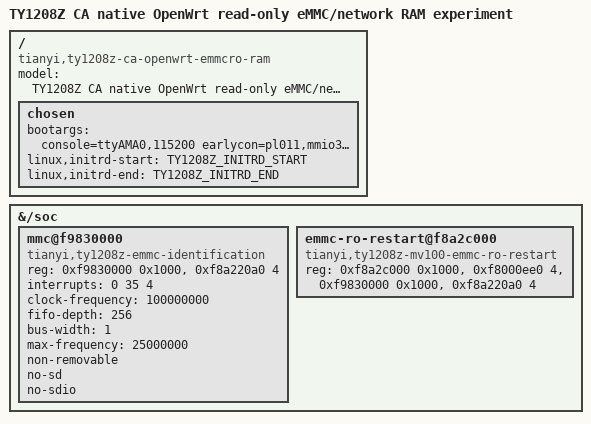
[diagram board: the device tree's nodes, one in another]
// SPDX-License-Identifier: GPL-2.0-only
#include "hi3798mv100-ty1208z-ethernet-net.dts"

/ {
	model = "TY1208Z CA native OpenWrt read-only eMMC/network RAM experiment";
	compatible = "tianyi,ty1208z-ca-openwrt-emmcro-ram", "hi3798mv100-series";
	chosen {
		bootargs = "console=ttyAMA0,115200 earlycon=pl011,mmio32,0xf8b00000 rdinit=/init loglevel=7 panic=0 blkdevparts=mmcblk0:1M(boot)ro,1M(bootargs)ro,4M(baseparam)ro,4M(pqparam)ro,4M(logo)ro,20M(kernel)ro,64M(busybox)ro,512M(backup)ro,6846M(ubuntu)ro";
		linux,initrd-start = <TY1208Z_INITRD_START>;
		linux,initrd-end = <TY1208Z_INITRD_END>;
	};
};

&{/soc} {
	mmc@f9830000 {
		compatible = "tianyi,ty1208z-emmc-identification";
		reg = <0xf9830000 0x1000>, <0xf8a220a0 4>;
		reg-names = "controller", "crg40";
		interrupts = <0 35 4>;
		clock-frequency = <100000000>;
		fifo-depth = <256>;
		bus-width = <1>;
		max-frequency = <25000000>;
		non-removable;
		no-sd;
		no-sdio;
	};
	emmc-ro-restart@f8a2c000 {
		compatible = "tianyi,ty1208z-mv100-emmc-ro-restart";
		reg = <0xf8a2c000 0x1000>, <0xf8000ee0 4>,
		      <0xf9830000 0x1000>, <0xf8a220a0 4>;
	};
};
